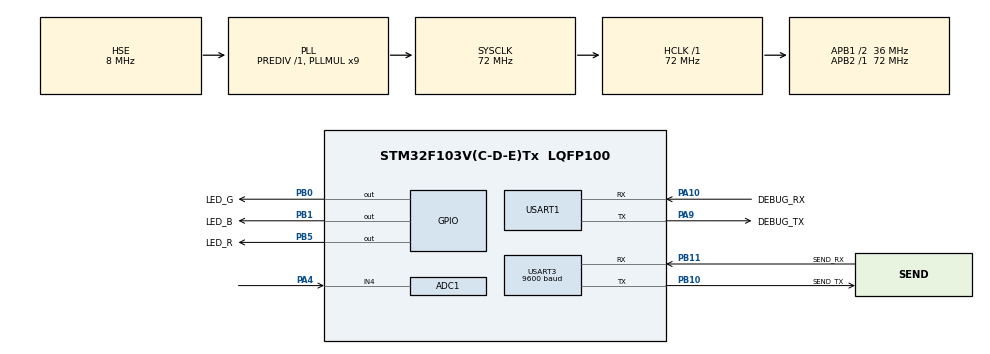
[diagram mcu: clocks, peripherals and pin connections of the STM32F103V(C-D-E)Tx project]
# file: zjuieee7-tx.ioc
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ADC1.Channel-1\#ChannelRegularConversion=ADC_CHANNEL_4
ADC1.ContinuousConvMode=ENABLE
ADC1.NbrOfConversionFlag=1
ADC1.Rank-1\#ChannelRegularConversion=1
ADC1.SamplingTime-1\#ChannelRegularConversion=ADC_SAMPLETIME_28CYCLES_5
ADC1.master=1
Dma.ADC1.0.Direction=DMA_PERIPH_TO_MEMORY
Dma.ADC1.0.Instance=DMA1_Channel1
Dma.ADC1.0.MemDataAlignment=DMA_MDATAALIGN_HALFWORD
Dma.ADC1.0.MemInc=DMA_MINC_ENABLE
Dma.ADC1.0.Mode=DMA_NORMAL
Dma.ADC1.0.PeriphDataAlignment=DMA_PDATAALIGN_HALFWORD
Dma.ADC1.0.PeriphInc=DMA_PINC_DISABLE
Dma.ADC1.0.Priority=DMA_PRIORITY_HIGH
Dma.Request0=ADC1
Mcu.Family=STM32F1
Mcu.Name=STM32F103V(C-D-E)Tx
Mcu.Package=LQFP100
NVIC.DMA1_Channel1_IRQn=true\:0\:0\:false\:false\:true\:false\:true
NVIC.PriorityGroup=NVIC_PRIORITYGROUP_4
NVIC.USART3_IRQn=true\:0\:0\:false\:false\:true\:true\:true
OSC_IN.Mode=HSE-External-Oscillator
OSC_IN.Signal=RCC_OSC_IN
OSC_OUT.Mode=HSE-External-Oscillator
OSC_OUT.Signal=RCC_OSC_OUT
PA10.GPIO_Label=DEBUG_RX
PA10.Mode=Asynchronous
PA10.Signal=USART1_RX
PA4.Signal=ADCx_IN4
PA9.GPIO_Label=DEBUG_TX
PA9.Mode=Asynchronous
PA9.Signal=USART1_TX
PB0.GPIO_Label=LED_G
PB0.GPIO_PuPd=GPIO_PULLUP
PB0.PinState=GPIO_PIN_SET
PB0.Signal=GPIO_Output
PB1.GPIO_Label=LED_B
PB1.GPIO_PuPd=GPIO_PULLUP
PB1.PinState=GPIO_PIN_SET
PB1.Signal=GPIO_Output
PB10.GPIO_Label=SEND_TX
PB10.Mode=Asynchronous
PB10.Signal=USART3_TX
PB11.GPIO_Label=SEND_RX
PB11.Mode=Asynchronous
PB11.Signal=USART3_RX
PB5.GPIO_Label=LED_R
PB5.GPIO_PuPd=GPIO_PULLUP
PB5.PinState=GPIO_PIN_SET
PB5.Signal=GPIO_Output
ProjectManager.HeapSize=0x200
ProjectManager.StackSize=0x400
ProjectManager.TargetToolchain=Makefile
RCC.ADCPresc=RCC_ADCPCLK2_DIV6
RCC.AHBFreq_Value=72000000
RCC.APB1CLKDivider=RCC_HCLK_DIV2
RCC.APB1Freq_Value=36000000
RCC.APB1TimFreq_Value=72000000
RCC.APB2Freq_Value=72000000
RCC.APB2TimFreq_Value=72000000
RCC.HCLKFreq_Value=72000000
RCC.PLLMUL=RCC_PLL_MUL9
RCC.PLLSourceVirtual=RCC_PLLSOURCE_HSE
RCC.SYSCLKFreq_VALUE=72000000
RCC.SYSCLKSource=RCC_SYSCLKSOURCE_PLLCLK
RCC.USBFreq_Value=72000000
SH.ADCx_IN4.0=ADC1_IN4,IN4
TIM6.Prescaler=72-1
USART1.VirtualMode=VM_ASYNC
USART3.BaudRate=9600
USART3.Mode=MODE_TX
USART3.VirtualMode=VM_ASYNC
VP_SYS_VS_ND.Mode=No_Debug
VP_TIM6_VS_ClockSourceINT.Mode=Enable_Timer
board=custom

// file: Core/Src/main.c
/* USER CODE BEGIN Header */
/**
  ******************************************************************************
  * @file           : main.c
  * @brief          : Main program body
  ******************************************************************************
  * @attention
  *
  * <h2><center>&copy; Copyright (c) 2021 STMicroelectronics.
  * All rights reserved.</center></h2>
  *
  * This software component is licensed by ST under BSD 3-Clause license,
  * the "License"; You may not use this file except in compliance with the
  * License. You may obtain a copy of the License at:
  *                        opensource.org/licenses/BSD-3-Clause
  *
  ******************************************************************************
  */
/* USER CODE END Header */
#include "main.h"
#include "adc.h"
#include "dma.h"
#include "tim.h"
#include "usart.h"
#include "gpio.h"

/* USER CODE BEGIN Includes */
#include "delay.h"
#include "led.h"
#include "tty.h"
#include "listen.h"
/* USER CODE END Includes */

void SystemClock_Config(void);

int main(void)
{

  /* MCU Configuration--------------------------------------------------------*/

  /* Reset of all peripherals, Initializes the Flash interface and the Systick. */
  HAL_Init();

  /* Configure the system clock */
  SystemClock_Config();

  /* Initialize all configured peripherals */
  MX_GPIO_Init();
  MX_DMA_Init();
  MX_TIM6_Init();
  MX_USART1_UART_Init();
  MX_USART3_UART_Init();
  MX_ADC1_Init();
  /* USER CODE BEGIN 2 */

  delay_init();
  LED_SetColor(LED_G);
  /* USER CODE END 2 */

  /* Infinite loop */
  /* USER CODE BEGIN WHILE */
  uint8_t res;
  while (1)
  {
    wait_for_signal();
    res = decode_signal();
    HAL_UART_Transmit(&huart3, &res, 1, 0xffff);
    /* USER CODE END WHILE */

  }
}

void SystemClock_Config(void)
{
  RCC_OscInitTypeDef RCC_OscInitStruct = {0};
  RCC_ClkInitTypeDef RCC_ClkInitStruct = {0};
  RCC_PeriphCLKInitTypeDef PeriphClkInit = {0};

  /** Initializes the RCC Oscillators according to the specified parameters
  * in the RCC_OscInitTypeDef structure.
  */
  RCC_OscInitStruct.OscillatorType = RCC_OSCILLATORTYPE_HSE;
  RCC_OscInitStruct.HSEState = RCC_HSE_ON;
  RCC_OscInitStruct.HSEPredivValue = RCC_HSE_PREDIV_DIV1;
  RCC_OscInitStruct.HSIState = RCC_HSI_ON;
  RCC_OscInitStruct.PLL.PLLState = RCC_PLL_ON;
  RCC_OscInitStruct.PLL.PLLSource = RCC_PLLSOURCE_HSE;
  RCC_OscInitStruct.PLL.PLLMUL = RCC_PLL_MUL9;
  if (HAL_RCC_OscConfig(&RCC_OscInitStruct) != HAL_OK)
  {
    Error_Handler();
  }
  /** Initializes the CPU, AHB and APB buses clocks
  */
  RCC_ClkInitStruct.ClockType = RCC_CLOCKTYPE_HCLK|RCC_CLOCKTYPE_SYSCLK
                              |RCC_CLOCKTYPE_PCLK1|RCC_CLOCKTYPE_PCLK2;
  RCC_ClkInitStruct.SYSCLKSource = RCC_SYSCLKSOURCE_PLLCLK;
  RCC_ClkInitStruct.AHBCLKDivider = RCC_SYSCLK_DIV1;
  RCC_ClkInitStruct.APB1CLKDivider = RCC_HCLK_DIV2;
  RCC_ClkInitStruct.APB2CLKDivider = RCC_HCLK_DIV1;

  if (HAL_RCC_ClockConfig(&RCC_ClkInitStruct, FLASH_LATENCY_2) != HAL_OK)
  {
    Error_Handler();
  }
  PeriphClkInit.PeriphClockSelection = RCC_PERIPHCLK_ADC;
  PeriphClkInit.AdcClockSelection = RCC_ADCPCLK2_DIV6;
  if (HAL_RCCEx_PeriphCLKConfig(&PeriphClkInit) != HAL_OK)
  {
    Error_Handler();
  }
}

void Error_Handler(void)
{
  /* USER CODE BEGIN Error_Handler_Debug */
  /* User can add his own implementation to report the HAL error return state */
  __disable_irq();
  LED_SetColor(LED_R);
  while (1)
  {
  }
  /* USER CODE END Error_Handler_Debug */
}

/************************ (C) COPYRIGHT STMicroelectronics *****END OF FILE****/
